# STM32H73x register map
File version: 1.3
CPU: CM7 r0p1, little endian, MPU, FPU, 4 interrupt priority bits
Registers are 32-bit, read-write, reset 0x0 unless marked. A register's access mark holds for its fields unless they carry their own. Offsets are from the block's base; [hi:lo] are bit positions; {n}, {i} and the like mark numbered series; 'fields as' and 'values as' point back to an identical list.

## OTG1_HS_PWRCLK — USB 1 on the go high speed
Base 0x40040E00
Same registers: OTG2_HS_PWRCLK 0x40080E00
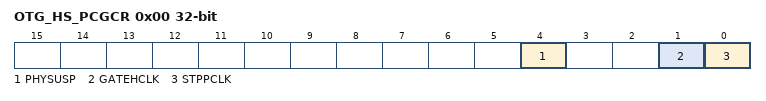
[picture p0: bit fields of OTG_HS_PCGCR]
0x00 OTG_HS_PCGCR — Power and clock gating control register
  [4] PHYSUSP — PHY suspended
  [1] GATEHCLK
  [0] STPPCLK — Stop PHY clock

## OctoSPII_O_Manager
Base 0x5200B400
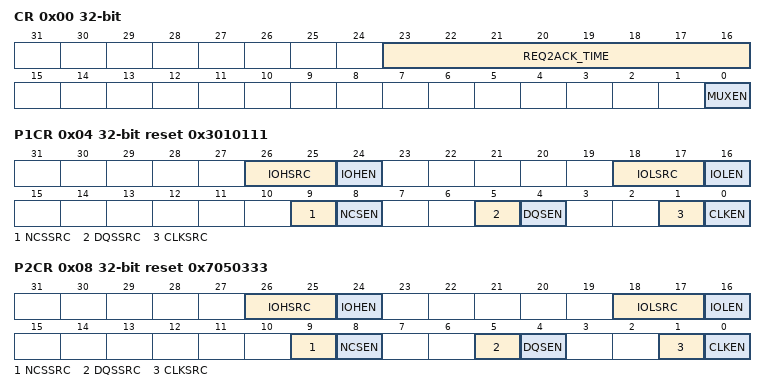
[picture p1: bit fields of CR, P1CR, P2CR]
0x00 CR — OctoSPI IO Manager Control Register
  [23:16] REQ2ACK_TIME — REQ to ACK Time
  [0] MUXEN — Multiplexed mode Enable
0x04 P1CR reset 0x3010111 — OctoSPI IO Manager Port 1 configuration register
  [26:25] IOHSRC
  [24] IOHEN
  [18:17] IOLSRC
  [16] IOLEN
  [9] NCSSRC
  [8] NCSEN
  [5] DQSSRC
  [4] DQSEN
  [1] CLKSRC — CLK/CLKn Source for Port n
  [0] CLKEN — CLK/CLKn Enable for Port n
0x08 P2CR reset 0x7050333 — OctoSPI IO Manager Port 2 configuration register
  [26:25] IOHSRC, [24] IOHEN, [18:17] IOLSRC, [16] IOLEN, [9] NCSSRC, [8] NCSEN, [5] DQSSRC, [4] DQSEN, [1] CLKSRC, [0] CLKEN

## PF — Processor features
Base 0xE000ED78
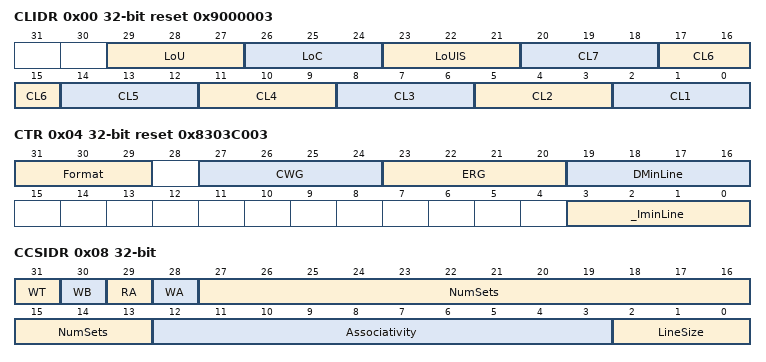
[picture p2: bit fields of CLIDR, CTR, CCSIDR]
0x00 CLIDR ro reset 0x9000003 — Cache Level ID register
  [29:27] LoU, [26:24] LoC, [23:21] LoUIS, [3n-1:3n-3] CL{n} (n=1..7)
0x04 CTR ro reset 0x8303C003 — Cache Type register
  [31:29] Format, [27:24] CWG, [23:20] ERG, [19:16] DMinLine, [3:0] _IminLine
0x08 CCSIDR ro — Cache Size ID register
  [31] WT, [30] WB, [29] RA, [28] WA, [27:13] NumSets, [12:3] Associativity, [2:0] LineSize

## RAMECC1 — ECC controller is associated to each RAM area
Base 0x52009000
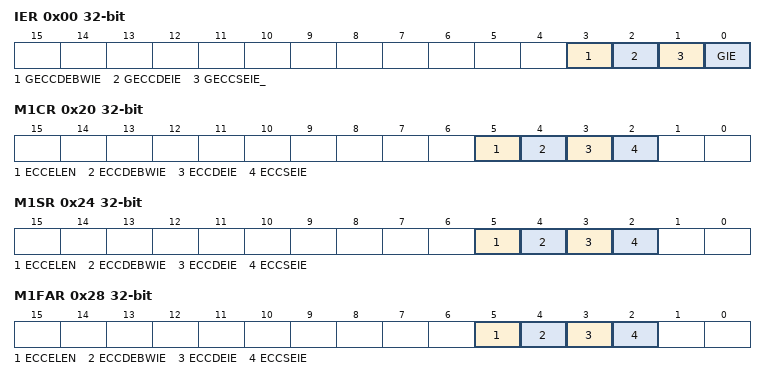
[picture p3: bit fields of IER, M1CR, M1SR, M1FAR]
0x00 IER — RAMECC interrupt enable register
  [3] GECCDEBWIE — Global ECC double error on byte write (BW) interrupt enable
  [2] GECCDEIE — Global ECC double error interrupt enable
  [1] GECCSEIE_ — Global ECC single error interrupt enable
  [0] GIE — Global interrupt enable
0x20 M1CR — RAMECC monitor x configuration register
  [5] ECCELEN — ECC error latching enable
  [4] ECCDEBWIE — ECC double error on byte write (BW) interrupt enable
  [3] ECCDEIE — ECC double error interrupt enable
  [2] ECCSEIE — ECC single error interrupt enable
0x24 M1SR — RAMECC monitor x status register
  fields as M1CR
0x28 M1FAR — RAMECC monitor x failing address register
  fields as M1CR
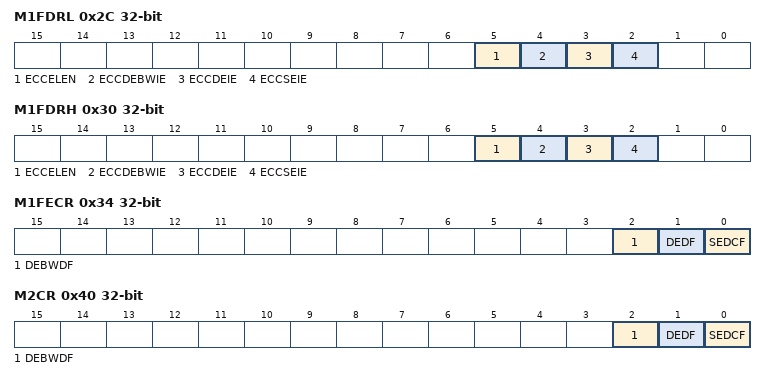
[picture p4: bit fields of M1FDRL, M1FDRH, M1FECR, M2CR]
0x2C M1FDRL — RAMECC monitor x failing data low register
  fields as M1CR
0x30 M1FDRH — RAMECC monitor x failing data high register
  fields as M1CR
0x34 M1FECR — RAMECC monitor x failing ECC error code register
  [2] DEBWDF — ECC double error on byte write (BW) detected flag
  [1] DEDF — ECC double error detected flag
  [0] SEDCF — ECC single error detected and corrected flag
0x40 M2CR — RAMECC monitor x configuration register
  fields as M1FECR
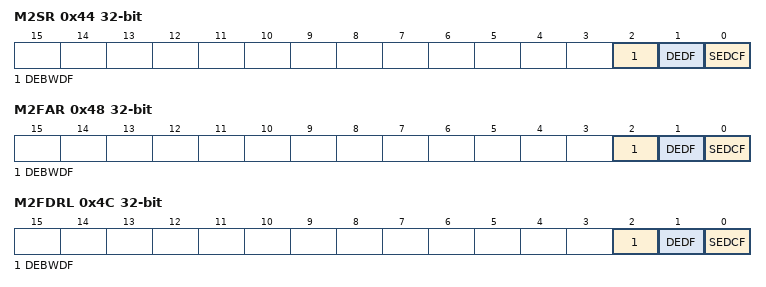
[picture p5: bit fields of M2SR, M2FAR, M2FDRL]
0x44 M2SR — RAMECC monitor x status register
  fields as M1FECR
0x48 M2FAR — RAMECC monitor x failing address register
  fields as M1FECR
0x4C M2FDRL — RAMECC monitor x failing data low register
  fields as M1FECR
0x50 M2FDRH ro — RAMECC monitor x failing data high register
  [31:0] FADD — ECC error failing address
0x58 M2FECR ro — RAMECC monitor x failing ECC error code register
  [31:0] FADD — ECC error failing address
0x60 M3CR ro — RAMECC monitor x configuration register
  [31:0] FADD — ECC error failing address
0x64 M3SR ro — RAMECC monitor x status register
  [31:0] FADD — ECC error failing address
0x68 M3FAR — RAMECC monitor x failing address register
  [31:0] FADD — ECC error failing address
0x6C M3FDRL ro — RAMECC monitor x failing data low register
  [31:0] FDATAL — Failing data low
0x70 M3FDRH ro — RAMECC monitor x failing data high register
  [31:0] FDATAL — Failing data low
0x7C M3FECR ro — RAMECC monitor x failing ECC error code register
  [31:0] FDATAL — Failing data low
0x80 M4CR ro — RAMECC monitor x configuration register
  [31:0] FDATAL — Failing data low
0x84 M4SR ro — RAMECC monitor x status register
  [31:0] FDATAL — Failing data low
0x88 M4FAR ro — RAMECC monitor x failing address register
  [31:0] FDATAH — Failing data high (64-bit memory)
0x8C M4FDRL — RAMECC monitor x failing data low register
  [31:0] FDATAH — Failing data high (64-bit memory)
0x90 M4FDRH ro — RAMECC monitor x failing data high register
  [31:0] FDATAH — Failing data high (64-bit memory)
0x90 M4FECR ro (alternate view of M4FDRH) — RAMECC monitor x failing ECC error code register
  [31:0] FDATAH — Failing data high (64-bit memory)
0xA0 M5CR ro — RAMECC monitor x configuration register
  [31:0] FEC — Failing error code
0xA4 M5SR — RAMECC monitor x status register
  [31:0] FEC — Failing error code
0xA8 M5FAR — RAMECC monitor x failing address register
  [31:0] FEC — Failing error code
0xAC M5FDRL ro — RAMECC monitor x failing data low register
  [31:0] FEC — Failing error code
0xB0 M5FDRH ro — RAMECC monitor x failing data high register
  [31:0] FEC — Failing error code
0xB4 M5FECR ro — RAMECC monitor x failing ECC error code register
  [31:0] FEC — Failing error code
